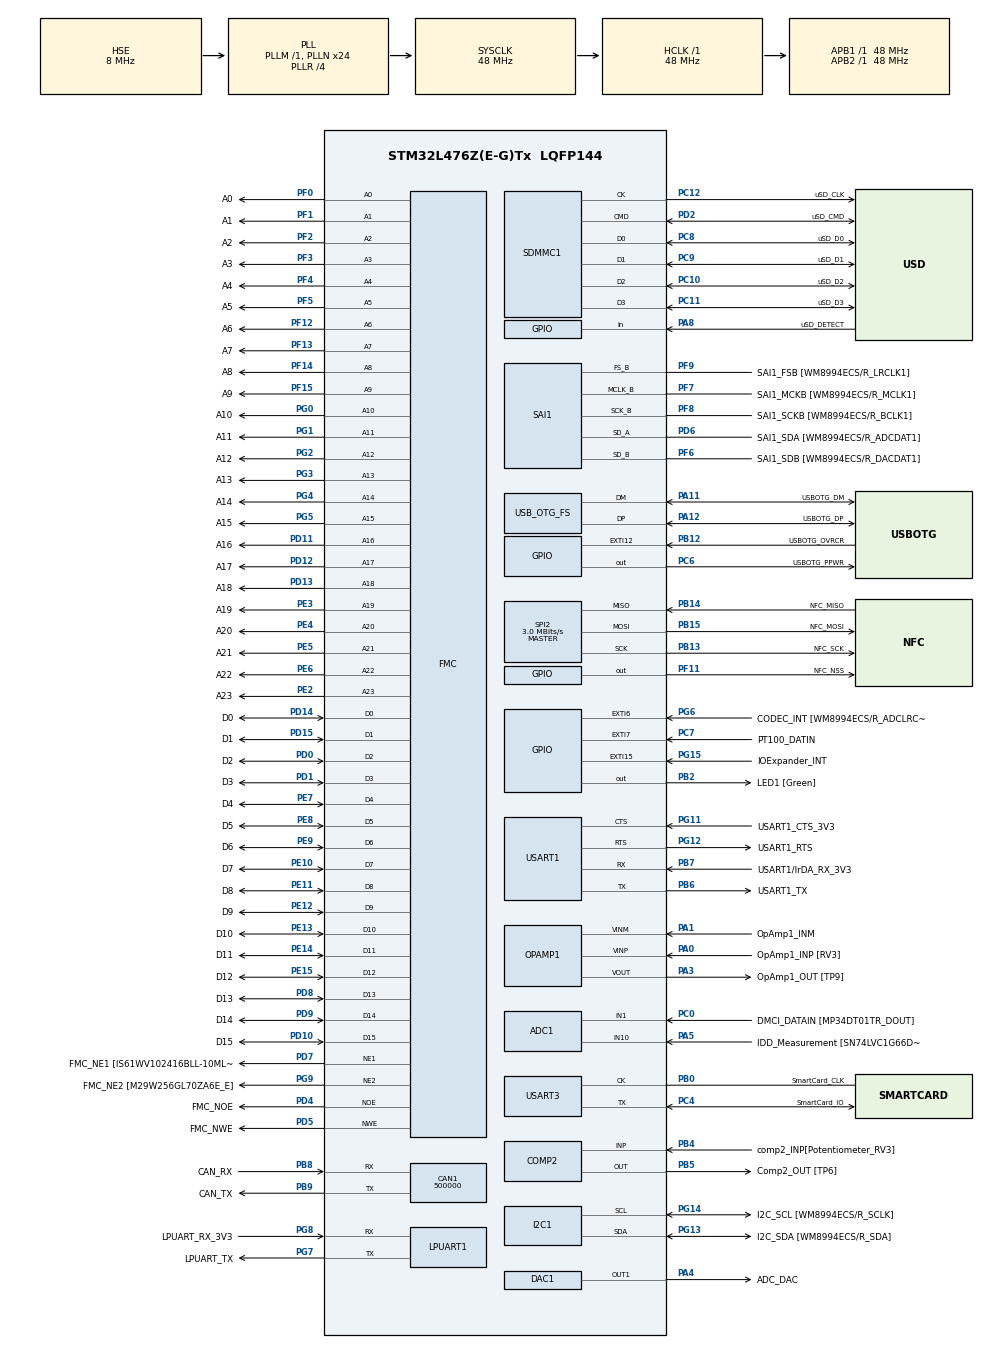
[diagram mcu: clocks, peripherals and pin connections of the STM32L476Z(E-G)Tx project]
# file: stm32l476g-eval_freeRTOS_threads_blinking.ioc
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ADC1.Channel-0\#ChannelRegularConversion=ADC_CHANNEL_10
ADC1.NbrOfConversionFlag=1
ADC1.Offset-0\#ChannelRegularConversion=0
ADC1.OffsetNumber-0\#ChannelRegularConversion=ADC_OFFSET_NONE
ADC1.Rank-0\#ChannelRegularConversion=1
ADC1.SamplingTime-0\#ChannelRegularConversion=ADC_SAMPLETIME_2CYCLES_5
ADC1.master=1
CAN1.BS1=CAN_BS1_1TQ
CAN1.BS2=CAN_BS2_4TQ
CAN1.CalculateBaudRate=500000
CAN1.CalculateTimeBit=2000
CAN1.CalculateTimeQuantum=333.3333333333333
FREERTOS.Tasks01=blink01,24,128,StartBlink01,Default,NULL,Dynamic,NULL,NULL;blink02,16,128,StartBlink02,Default,NULL,Dynamic,NULL,NULL
I2C1.Timing=0x20303E5D
Mcu.Family=STM32L4
Mcu.Name=STM32L476Z(E-G)Tx
Mcu.Package=LQFP144
NVIC.OTG_FS_IRQn=true\:5\:0\:false\:false\:true\:true\:true\:true\:true
NVIC.PriorityGroup=NVIC_PRIORITYGROUP_4
NVIC.TIM6_DAC_IRQn=true\:15\:0\:false\:false\:true\:false\:false\:true\:true
NVIC.TIM7_IRQn=true\:15\:0\:false\:false\:true\:false\:false\:true\:true
NVIC.TimeBase=TIM7_IRQn
NVIC.TimeBaseIP=TIM7
PA0.GPIO_Label=OpAmp1_INP [RV3]
PA0.GPIO_Mode=GPIO_MODE_ANALOG
PA0.GPIO_PuPd=GPIO_NOPULL
PA0.Mode=Standalone
PA0.Signal=OPAMP1_VINP
PA1.GPIO_Label=OpAmp1_INM
PA1.Mode=Standalone
PA1.Signal=OPAMP1_VINM
PA10.GPIO_Label=USBOTG_ID
PA10.Signal=USB_OTG_FS_ID
PA11.GPIO_Label=USBOTG_DM
PA11.GPIO_Mode=GPIO_MODE_AF_PP
PA11.GPIO_PuPd=GPIO_NOPULL
PA11.GPIO_Speed=GPIO_SPEED_FREQ_VERY_HIGH
PA11.Mode=Host_Only
PA11.Signal=USB_OTG_FS_DM
PA12.GPIO_Label=USBOTG_DP
PA12.GPIO_Mode=GPIO_MODE_AF_PP
PA12.GPIO_PuPd=GPIO_NOPULL
PA12.GPIO_Speed=GPIO_SPEED_FREQ_VERY_HIGH
PA12.Mode=Host_Only
PA12.Signal=USB_OTG_FS_DP
PA13\ (JTMS-SWDIO).GPIO_Label=TMS/SWDIO
PA13\ (JTMS-SWDIO).Mode=Serial_Wire
PA13\ (JTMS-SWDIO).Signal=SYS_JTMS-SWDIO
PA14\ (JTCK-SWCLK).GPIO_Label=TMS/SWCLK
PA14\ (JTCK-SWCLK).Mode=Serial_Wire
PA14\ (JTCK-SWCLK).Signal=SYS_JTCK-SWCLK
PA3.GPIO_Label=OpAmp1_OUT [TP9]
PA3.Mode=Standalone
PA3.Signal=OPAMP1_VOUT
PA4.GPIO_Label=ADC_DAC
PA4.GPIO_Mode=GPIO_MODE_ANALOG
PA4.GPIO_PuPd=GPIO_NOPULL
PA4.Signal=COMP_DAC11_group
PA5.GPIO_Label=IDD_Measurement [SN74LVC1G66DCKT_O/I]
PA5.GPIO_Mode=GPIO_MODE_ANALOG_ADC_CONTROL
PA5.GPIO_PuPd=GPIO_NOPULL
PA5.Signal=ADCx_IN10
PA8.GPIO_Label=uSD_DETECT
PA8.Signal=GPIO_Input
PA9.GPIO_Label=USBOTG_VBUS
PA9.Signal=USB_OTG_FS_VBUS
PB0.GPIO_Label=SmartCard_CLK
PB0.Mode=SmartCard_With_Clock
PB0.Signal=USART3_CK
PB12.GPIO_Label=USBOTG_OVRCR
PB12.Signal=GPXTI12
PB13.GPIO_Label=NFC_SCK
PB13.Mode=Full_Duplex_Master
PB13.Signal=SPI2_SCK
PB14.GPIO_Label=NFC_MISO
PB14.Mode=Full_Duplex_Master
PB14.Signal=SPI2_MISO
PB15.GPIO_Label=NFC_MOSI
PB15.Mode=Full_Duplex_Master
PB15.Signal=SPI2_MOSI
PB2.GPIO_Label=LED1 [Green]
PB2.GPIO_ModeDefaultOutputPP=GPIO_MODE_OUTPUT_PP
PB2.GPIO_PuPd=GPIO_NOPULL
PB2.GPIO_Speed=GPIO_SPEED_FREQ_LOW
PB2.Signal=GPIO_Output
PB4\ (NJTRST).GPIO_Label=comp2_INP[Potentiometer_RV3]
PB4\ (NJTRST).Mode=INP
PB4\ (NJTRST).Signal=COMP2_INP
PB5.GPIO_Label=Comp2_OUT [TP6]
PB5.Mode=ExternalOutput
PB5.Signal=COMP2_OUT
PB6.GPIO_FM6=__NULL
PB6.GPIO_Label=USART1_TX
PB6.GPIO_Mode=GPIO_MODE_AF_PP
PB6.GPIO_PuPd=GPIO_PULLUP
PB6.GPIO_Speed=GPIO_SPEED_FREQ_VERY_HIGH
PB6.Mode=Asynchronous
PB6.Signal=USART1_TX
PB7.GPIO_FM7=__NULL
PB7.GPIO_Label=USART1/IrDA_RX_3V3
PB7.GPIO_Mode=GPIO_MODE_AF_PP
PB7.GPIO_PuPd=GPIO_PULLUP
PB7.GPIO_Speed=GPIO_SPEED_FREQ_VERY_HIGH
PB7.Mode=Asynchronous
PB7.Signal=USART1_RX
PB8.GPIO_Label=CAN_RX
PB8.Mode=CAN_Activate
PB8.Signal=CAN1_RX
PB9.GPIO_Label=CAN_TX
PB9.Mode=CAN_Activate
PB9.Signal=CAN1_TX
PC0.GPIO_Label=DMCI_DATAIN [MP34DT01TR_DOUT]
PC0.Signal=ADCx_IN1
PC10.GPIO_Label=uSD_D2
PC10.Mode=SD_4_bits_Wide_bus
PC10.Signal=SDMMC1_D2
PC11.GPIO_Label=uSD_D3
PC11.Mode=SD_4_bits_Wide_bus
PC11.Signal=SDMMC1_D3
PC12.GPIO_Label=uSD_CLK
PC12.Mode=SD_4_bits_Wide_bus
PC12.Signal=SDMMC1_CK
PC13.GPIO_Label=Key [B2]
PC13.Signal=SYS_WKUP2
PC14-OSC32_IN\ (PC14).Mode=LSE-External-Oscillator
PC14-OSC32_IN\ (PC14).Signal=RCC_OSC32_IN
PC15-OSC32_OUT\ (PC15).Mode=LSE-External-Oscillator
PC15-OSC32_OUT\ (PC15).Signal=RCC_OSC32_OUT
PC3.GPIO_Label=VLCD
PC3.GPIO_Mode=GPIO_MODE_AF_PP
PC3.GPIO_PuPd=GPIO_NOPULL
PC3.GPIO_Speed=GPIO_SPEED_FREQ_LOW
PC3.Signal=LCD_VLCD
PC4.GPIO_Label=SmartCard_IO
PC4.Mode=SmartCard_With_Clock
PC4.Signal=USART3_TX
PC5.GPIO_Label=IDD_WAKEUP
PC5.Signal=SYS_WKUP5
PC6.GPIO_Label=USBOTG_PPWR
PC6.Signal=GPIO_Output
PC7.GPIO_Label=PT100_DATIN
PC7.Signal=GPXTI7
PC8.GPIO_Label=uSD_D0
PC8.Mode=SD_4_bits_Wide_bus
PC8.Signal=SDMMC1_D0
PC9.GPIO_Label=uSD_D1
PC9.Mode=SD_4_bits_Wide_bus
PC9.Signal=SDMMC1_D1
PD0.GPIO_Label=D2
PD0.GPIO_Mode=GPIO_MODE_AF_PP
PD0.GPIO_PuPd=GPIO_NOPULL
PD0.GPIO_Speed=GPIO_SPEED_FREQ_VERY_HIGH
PD0.Signal=FMC_D2_DA2
PD1.GPIO_Label=D3
PD1.GPIO_Mode=GPIO_MODE_AF_PP
PD1.GPIO_PuPd=GPIO_NOPULL
PD1.GPIO_Speed=GPIO_SPEED_FREQ_VERY_HIGH
PD1.Signal=FMC_D3_DA3
PD10.GPIO_Label=D15
PD10.Signal=FMC_D15_DA15
PD11.GPIO_Label=A16
PD11.Signal=FMC_A16_CLE
PD12.GPIO_Label=A17
PD12.Signal=FMC_A17_ALE
PD13.GPIO_Label=A18
PD13.Signal=FMC_A18
PD14.GPIO_Label=D0
PD14.Signal=FMC_D0_DA0
PD15.GPIO_Label=D1
PD15.Signal=FMC_D1_DA1
PD2.GPIO_Label=uSD_CMD
PD2.Mode=SD_4_bits_Wide_bus
PD2.Signal=SDMMC1_CMD
PD4.GPIO_Label=FMC_NOE
PD4.GPIO_Mode=GPIO_MODE_AF_PP
PD4.GPIO_PuPd=GPIO_NOPULL
PD4.GPIO_Speed=GPIO_SPEED_FREQ_VERY_HIGH
PD4.Signal=FMC_NOE
PD5.GPIO_Label=FMC_NWE
PD5.GPIO_Mode=GPIO_MODE_AF_PP
PD5.GPIO_PuPd=GPIO_NOPULL
PD5.GPIO_Speed=GPIO_SPEED_FREQ_VERY_HIGH
PD5.Signal=FMC_NWE
PD6.GPIO_Label=SAI1_SDA [WM8994ECS/R_ADCDAT1]
PD6.GPIO_Mode=GPIO_MODE_AF_PP
PD6.GPIO_PuPd=GPIO_NOPULL
PD6.GPIO_Speed=GPIO_SPEED_FREQ_LOW
PD6.Mode=SAI_A_SPDIF
PD6.Signal=SAI1_SD_A
PD7.GPIO_Label=FMC_NE1 [IS61WV102416BLL-10MLI_CE]
PD7.GPIO_Mode=GPIO_MODE_AF_PP
PD7.GPIO_PuPd=GPIO_NOPULL
PD7.GPIO_Speed=GPIO_SPEED_FREQ_VERY_HIGH
PD7.Mode=NorPsramChipSelect1_2
PD7.Signal=FMC_NE1
PD8.GPIO_Label=D13
PD8.Signal=FMC_D13_DA13
PD9.GPIO_Label=D14
PD9.Signal=FMC_D14_DA14
PE0.GPIO_Label=FMC_NBL0 [IS61WV102416BLL-10MLI_BLE]
PE0.Signal=FMC_NBL0
PE1.GPIO_Label=FMC_NBL1 [IS61WV102416BLL-10MLI_BHE]
PE1.Signal=FMC_NBL1
PE10.GPIO_Label=D7
PE10.GPIO_Mode=GPIO_MODE_AF_PP
PE10.GPIO_PuPd=GPIO_NOPULL
PE10.GPIO_Speed=GPIO_SPEED_FREQ_VERY_HIGH
PE10.Signal=FMC_D7_DA7
PE11.GPIO_Label=D8
PE11.GPIO_Mode=GPIO_MODE_AF_PP
PE11.GPIO_PuPd=GPIO_NOPULL
PE11.GPIO_Speed=GPIO_SPEED_FREQ_VERY_HIGH
PE11.Signal=FMC_D8_DA8
PE12.GPIO_Label=D9
PE12.GPIO_Mode=GPIO_MODE_AF_PP
PE12.GPIO_PuPd=GPIO_NOPULL
PE12.GPIO_Speed=GPIO_SPEED_FREQ_VERY_HIGH
PE12.Signal=FMC_D9_DA9
PE13.GPIO_Label=D10
PE13.GPIO_Mode=GPIO_MODE_AF_PP
PE13.GPIO_PuPd=GPIO_NOPULL
PE13.GPIO_Speed=GPIO_SPEED_FREQ_VERY_HIGH
PE13.Signal=FMC_D10_DA10
PE14.GPIO_Label=D11
PE14.GPIO_Mode=GPIO_MODE_AF_PP
PE14.GPIO_PuPd=GPIO_NOPULL
PE14.GPIO_Speed=GPIO_SPEED_FREQ_VERY_HIGH
PE14.Signal=FMC_D11_DA11
PE15.GPIO_Label=D12
PE15.GPIO_Mode=GPIO_MODE_AF_PP
PE15.GPIO_PuPd=GPIO_NOPULL
PE15.GPIO_Speed=GPIO_SPEED_FREQ_VERY_HIGH
PE15.Signal=FMC_D12_DA12
PE2.GPIO_Label=A23
PE2.Signal=FMC_A23
PE3.GPIO_Label=A19
PE3.Signal=FMC_A19
PE4.GPIO_Label=A20
PE4.GPIO_Mode=GPIO_MODE_AF_PP
PE4.GPIO_PuPd=GPIO_NOPULL
PE4.GPIO_Speed=GPIO_SPEED_FREQ_VERY_HIGH
PE4.Signal=FMC_A20
PE5.GPIO_Label=A21
PE5.GPIO_Mode=GPIO_MODE_AF_PP
PE5.GPIO_PuPd=GPIO_NOPULL
PE5.GPIO_Speed=GPIO_SPEED_FREQ_VERY_HIGH
PE5.Signal=FMC_A21
PE6.GPIO_Label=A22
PE6.GPIO_Mode=GPIO_MODE_AF_PP
PE6.GPIO_PuPd=GPIO_NOPULL
PE6.GPIO_Speed=GPIO_SPEED_FREQ_VERY_HIGH
PE6.Signal=FMC_A22
PE7.GPIO_Label=D4
PE7.GPIO_Mode=GPIO_MODE_AF_PP
PE7.GPIO_PuPd=GPIO_NOPULL
PE7.GPIO_Speed=GPIO_SPEED_FREQ_VERY_HIGH
PE7.Signal=FMC_D4_DA4
PE8.GPIO_Label=D5
PE8.GPIO_Mode=GPIO_MODE_AF_PP
PE8.GPIO_PuPd=GPIO_NOPULL
PE8.GPIO_Speed=GPIO_SPEED_FREQ_VERY_HIGH
PE8.Signal=FMC_D5_DA5
PE9.GPIO_Label=D6
PE9.GPIO_Mode=GPIO_MODE_AF_PP
PE9.GPIO_PuPd=GPIO_NOPULL
PE9.GPIO_Speed=GPIO_SPEED_FREQ_VERY_HIGH
PE9.Signal=FMC_D6_DA6
PF0.GPIO_Label=A0
PF0.GPIO_Mode=GPIO_MODE_AF_PP
PF0.GPIO_PuPd=GPIO_NOPULL
PF0.GPIO_Speed=GPIO_SPEED_FREQ_VERY_HIGH
PF0.Signal=FMC_A0
PF1.GPIO_Label=A1
PF1.GPIO_Mode=GPIO_MODE_AF_PP
PF1.GPIO_PuPd=GPIO_NOPULL
PF1.GPIO_Speed=GPIO_SPEED_FREQ_VERY_HIGH
PF1.Signal=FMC_A1
PF11.GPIO_Label=NFC_NSS
PF11.GPIO_ModeDefaultOutputPP=GPIO_MODE_OUTPUT_PP
PF11.GPIO_PuPd=GPIO_NOPULL
PF11.GPIO_Speed=GPIO_SPEED_FREQ_LOW
PF11.Signal=GPIO_Output
PF12.GPIO_Label=A6
PF12.GPIO_Mode=GPIO_MODE_AF_PP
PF12.GPIO_PuPd=GPIO_NOPULL
PF12.GPIO_Speed=GPIO_SPEED_FREQ_VERY_HIGH
PF12.Signal=FMC_A6
PF13.GPIO_Label=A7
PF13.GPIO_Mode=GPIO_MODE_AF_PP
PF13.GPIO_PuPd=GPIO_NOPULL
PF13.GPIO_Speed=GPIO_SPEED_FREQ_VERY_HIGH
PF13.Signal=FMC_A7
PF14.GPIO_Label=A8
PF14.GPIO_Mode=GPIO_MODE_AF_PP
PF14.GPIO_PuPd=GPIO_NOPULL
PF14.GPIO_Speed=GPIO_SPEED_FREQ_VERY_HIGH
PF14.Signal=FMC_A8
PF15.GPIO_Label=A9
PF15.GPIO_Mode=GPIO_MODE_AF_PP
PF15.GPIO_PuPd=GPIO_NOPULL
PF15.GPIO_Speed=GPIO_SPEED_FREQ_VERY_HIGH
PF15.Signal=FMC_A9
PF2.GPIO_Label=A2
PF2.GPIO_Mode=GPIO_MODE_AF_PP
PF2.GPIO_PuPd=GPIO_NOPULL
PF2.GPIO_Speed=GPIO_SPEED_FREQ_VERY_HIGH
PF2.Signal=FMC_A2
PF3.GPIO_Label=A3
PF3.GPIO_Mode=GPIO_MODE_AF_PP
PF3.GPIO_PuPd=GPIO_NOPULL
PF3.GPIO_Speed=GPIO_SPEED_FREQ_VERY_HIGH
PF3.Signal=FMC_A3
PF4.GPIO_Label=A4
PF4.GPIO_Mode=GPIO_MODE_AF_PP
PF4.GPIO_PuPd=GPIO_NOPULL
PF4.GPIO_Speed=GPIO_SPEED_FREQ_VERY_HIGH
PF4.Signal=FMC_A4
PF5.GPIO_Label=A5
PF5.GPIO_Mode=GPIO_MODE_AF_PP
PF5.GPIO_PuPd=GPIO_NOPULL
PF5.GPIO_Speed=GPIO_SPEED_FREQ_VERY_HIGH
PF5.Signal=FMC_A5
PF6.GPIO_Label=SAI1_SDB [WM8994ECS/R_DACDAT1]
PF6.GPIO_Mode=GPIO_MODE_AF_PP
PF6.GPIO_PuPd=GPIO_NOPULL
PF6.GPIO_Speed=GPIO_SPEED_FREQ_LOW
PF6.Mode=SAI_B_MasterWithClock
PF6.Signal=SAI1_SD_B
PF7.GPIO_Label=SAI1_MCKB [WM8994ECS/R_MCLK1]
PF7.GPIO_Mode=GPIO_MODE_AF_PP
PF7.GPIO_PuPd=GPIO_NOPULL
PF7.GPIO_Speed=GPIO_SPEED_FREQ_LOW
PF7.Mode=SAI_B_MasterWithClock
PF7.Signal=SAI1_MCLK_B
PF8.GPIO_Label=SAI1_SCKB [WM8994ECS/R_BCLK1]
PF8.GPIO_Mode=GPIO_MODE_AF_PP
PF8.GPIO_PuPd=GPIO_NOPULL
PF8.GPIO_Speed=GPIO_SPEED_FREQ_LOW
PF8.Mode=SAI_B_MasterWithClock
PF8.Signal=SAI1_SCK_B
PF9.GPIO_Label=SAI1_FSB [WM8994ECS/R_LRCLK1]
PF9.GPIO_Mode=GPIO_MODE_AF_PP
PF9.GPIO_PuPd=GPIO_NOPULL
PF9.GPIO_Speed=GPIO_SPEED_FREQ_LOW
PF9.Mode=SAI_B_MasterWithClock
PF9.Signal=SAI1_FS_B
PG0.GPIO_Label=A10
PG0.GPIO_Mode=GPIO_MODE_AF_PP
PG0.GPIO_PuPd=GPIO_NOPULL
PG0.GPIO_Speed=GPIO_SPEED_FREQ_VERY_HIGH
PG0.Signal=FMC_A10
PG1.GPIO_Label=A11
PG1.GPIO_Mode=GPIO_MODE_AF_PP
PG1.GPIO_PuPd=GPIO_NOPULL
PG1.GPIO_Speed=GPIO_SPEED_FREQ_VERY_HIGH
PG1.Signal=FMC_A11
PG10.GPIO_Label=LCD_NE3 [SN74LVC16T245DGGR_OE]
PG10.GPIO_Mode=GPIO_MODE_AF_PP
PG10.GPIO_PuPd=GPIO_NOPULL
PG10.GPIO_Speed=GPIO_SPEED_FREQ_VERY_HIGH
PG10.Signal=FMC_NE3
PG11.GPIO_Label=USART1_CTS_3V3
PG11.GPIO_Mode=GPIO_MODE_AF_PP
PG11.GPIO_PuPd=GPIO_NOPULL
PG11.GPIO_Speed=GPIO_SPEED_FREQ_VERY_HIGH
PG11.Mode=CTS_RTS
PG11.Signal=USART1_CTS
PG12.GPIO_Label=USART1_RTS
PG12.GPIO_Mode=GPIO_MODE_AF_PP
PG12.GPIO_PuPd=GPIO_NOPULL
PG12.GPIO_Speed=GPIO_SPEED_FREQ_VERY_HIGH
PG12.Mode=CTS_RTS
PG12.Signal=USART1_RTS
PG13.GPIO_Label=I2C_SDA [WM8994ECS/R_SDA]
PG13.GPIO_Mode=GPIO_MODE_AF_OD
PG13.GPIO_Pu=GPIO_PULLUP
PG13.GPIO_Speed=GPIO_SPEED_FREQ_VERY_HIGH
PG13.Mode=I2C
PG13.Signal=I2C1_SDA
PG14.GPIO_Label=I2C_SCL [WM8994ECS/R_SCLK]
PG14.GPIO_Mode=GPIO_MODE_AF_OD
PG14.GPIO_Pu=GPIO_PULLUP
PG14.GPIO_Speed=GPIO_SPEED_FREQ_VERY_HIGH
PG14.Mode=I2C
PG14.Signal=I2C1_SCL
PG15.GPIO_Label=IOExpander_INT
PG15.GPIO_ModeDefaultEXTI=GPIO_MODE_EVT_RISING
PG15.GPIO_PuPd=GPIO_NOPULL
PG15.Signal=GPXTI15
PG2.GPIO_Label=A12
PG2.GPIO_Mode=GPIO_MODE_AF_PP
PG2.GPIO_PuPd=GPIO_NOPULL
PG2.GPIO_Speed=GPIO_SPEED_FREQ_VERY_HIGH
PG2.Signal=FMC_A12
PG3.GPIO_Label=A13
PG3.GPIO_Mode=GPIO_MODE_AF_PP
PG3.GPIO_PuPd=GPIO_NOPULL
PG3.GPIO_Speed=GPIO_SPEED_FREQ_VERY_HIGH
PG3.Signal=FMC_A13
PG4.GPIO_Label=A14
PG4.GPIO_Mode=GPIO_MODE_AF_PP
PG4.GPIO_PuPd=GPIO_NOPULL
PG4.GPIO_Speed=GPIO_SPEED_FREQ_VERY_HIGH
PG4.Signal=FMC_A14
PG5.GPIO_Label=A15
PG5.GPIO_Mode=GPIO_MODE_AF_PP
PG5.GPIO_PuPd=GPIO_NOPULL
PG5.GPIO_Speed=GPIO_SPEED_FREQ_VERY_HIGH
PG5.Signal=FMC_A15
PG6.GPIO_Label=CODEC_INT [WM8994ECS/R_ADCLRCLK1/GPIO1]
PG6.GPIO_ModeDefaultEXTI=GPIO_MODE_EVT_RISING
PG6.GPIO_PuPd=GPIO_NOPULL
PG6.Signal=GPXTI6
PG7.GPIO_Label=LPUART_TX
PG7.GPIO_Mode=GPIO_MODE_AF_PP
PG7.GPIO_PuPd=GPIO_PULLUP
PG7.GPIO_Speed=GPIO_SPEED_FREQ_VERY_HIGH
PG7.Mode=Asynchronous
PG7.Signal=LPUART1_TX
PG8.GPIO_Label=LPUART_RX_3V3
PG8.GPIO_Mode=GPIO_MODE_AF_PP
PG8.GPIO_PuPd=GPIO_PULLUP
PG8.GPIO_Speed=GPIO_SPEED_FREQ_VERY_HIGH
PG8.Mode=Asynchronous
PG8.Signal=LPUART1_RX
PG9.GPIO_Label=FMC_NE2 [M29W256GL70ZA6E_E]
PG9.GPIO_Mode=GPIO_MODE_AF_PP
PG9.GPIO_PuPd=GPIO_NOPULL
PG9.GPIO_Speed=GPIO_SPEED_FREQ_VERY_HIGH
PG9.Mode=NorPsramChipSelect2_1
PG9.Signal=FMC_NE2
PH0-OSC_IN\ (PH0).Mode=HSE-External-Oscillator
PH0-OSC_IN\ (PH0).Signal=RCC_OSC_IN
PH1-OSC_OUT\ (PH1).Mode=HSE-External-Oscillator
PH1-OSC_OUT\ (PH1).Signal=RCC_OSC_OUT
ProjectManager.HeapSize=0x200
ProjectManager.StackSize=0x400
ProjectManager.TargetToolchain=STM32CubeIDE
RCC.ADCFreq_Value=48000000
RCC.AHBFreq_Value=48000000
RCC.APB1Freq_Value=48000000
RCC.APB1TimFreq_Value=48000000
RCC.APB2Freq_Value=48000000
RCC.APB2TimFreq_Value=48000000
RCC.CK48CLockSelection=RCC_USBCLKSOURCE_PLL
RCC.CortexFreq_Value=48000000
RCC.HCLKFreq_Value=48000000
RCC.HSE_VALUE=8000000
RCC.HSI_VALUE=16000000
RCC.MSI_VALUE=4000000
RCC.PLLN=24
RCC.PLLQ=RCC_PLLQ_DIV4
RCC.PLLR=RCC_PLLR_DIV4
RCC.PLLSAI1N=12
RCC.PLLSourceVirtual=RCC_PLLSOURCE_HSE
RCC.SYSCLKFreq_VALUE=48000000
RCC.SYSCLKSource=RCC_SYSCLKSOURCE_PLLCLK
RCC.USBFreq_Value=48000000
RCC.VCOOutputFreq_Value=192000000
SAI1.Instance-SAI_A_SPDIF=SAI$Index_Block_A
SAI1.Instance-SAI_B_MasterWithClock=SAI$Index_Block_B
SAI1.MClockEnable-SAI_B_MasterWithClock=SAI_MASTERCLOCK_ENABLE
SAI1.VirtualMode-SAI_A_SPDIF=VM_SPDIF
SAI1.VirtualMode-SAI_B_MasterWithClock=VM_MASTER
SDMMC1.WideMode=SDMMC_BUS_WIDE_4B
SH.ADCx_IN1.0=ADC1_IN1,IN1-Single-Ended
SH.ADCx_IN10.0=ADC1_IN10,IN10-Single-Ended
SH.COMP_DAC11_group.0=DAC1_OUT1,DAC_OUT1
SH.FMC_A0.0=FMC_A0,24b-a1
SH.FMC_A0.1=FMC_A0,22b-a2
SH.FMC_A1.0=FMC_A1,24b-a1
SH.FMC_A1.1=FMC_A1,22b-a2
SH.FMC_A10.0=FMC_A10,24b-a1
SH.FMC_A10.1=FMC_A10,22b-a2
SH.FMC_A11.0=FMC_A11,24b-a1
SH.FMC_A11.1=FMC_A11,22b-a2
SH.FMC_A12.0=FMC_A12,24b-a1
SH.FMC_A12.1=FMC_A12,22b-a2
SH.FMC_A13.0=FMC_A13,24b-a1
SH.FMC_A13.1=FMC_A13,22b-a2
SH.FMC_A14.0=FMC_A14,24b-a1
SH.FMC_A14.1=FMC_A14,22b-a2
SH.FMC_A15.0=FMC_A15,24b-a1
SH.FMC_A15.1=FMC_A15,22b-a2
SH.FMC_A16_CLE.0=FMC_A16,24b-a1
SH.FMC_A16_CLE.1=FMC_A16,22b-a2
SH.FMC_A17_ALE.0=FMC_A17,24b-a1
SH.FMC_A17_ALE.1=FMC_A17,22b-a2
SH.FMC_A18.0=FMC_A18,24b-a1
SH.FMC_A18.1=FMC_A18,22b-a2
SH.FMC_A19.0=FMC_A19,24b-a1
SH.FMC_A19.1=FMC_A19,22b-a2
SH.FMC_A2.0=FMC_A2,24b-a1
SH.FMC_A2.1=FMC_A2,22b-a2
SH.FMC_A20.0=FMC_A20,24b-a1
SH.FMC_A20.1=FMC_A20,22b-a2
SH.FMC_A21.0=FMC_A21,24b-a1
SH.FMC_A21.1=FMC_A21,22b-a2
SH.FMC_A22.0=FMC_A22,24b-a1
SH.FMC_A23.0=FMC_A23,24b-a1
SH.FMC_A3.0=FMC_A3,24b-a1
SH.FMC_A3.1=FMC_A3,22b-a2
SH.FMC_A4.0=FMC_A4,24b-a1
SH.FMC_A4.1=FMC_A4,22b-a2
SH.FMC_A5.0=FMC_A5,24b-a1
SH.FMC_A5.1=FMC_A5,22b-a2
SH.FMC_A6.0=FMC_A6,24b-a1
SH.FMC_A6.1=FMC_A6,22b-a2
SH.FMC_A7.0=FMC_A7,24b-a1
SH.FMC_A7.1=FMC_A7,22b-a2
SH.FMC_A8.0=FMC_A8,24b-a1
SH.FMC_A8.1=FMC_A8,22b-a2
SH.FMC_A9.0=FMC_A9,24b-a1
SH.FMC_A9.1=FMC_A9,22b-a2
SH.FMC_D0_DA0.0=FMC_D0,16b-d1
SH.FMC_D0_DA0.1=FMC_D0,16b-d2
SH.FMC_D10_DA10.0=FMC_D10,16b-d1
SH.FMC_D10_DA10.1=FMC_D10,16b-d2
SH.FMC_D11_DA11.0=FMC_D11,16b-d1
SH.FMC_D11_DA11.1=FMC_D11,16b-d2
SH.FMC_D12_DA12.0=FMC_D12,16b-d1
SH.FMC_D12_DA12.1=FMC_D12,16b-d2
SH.FMC_D13_DA13.0=FMC_D13,16b-d1
SH.FMC_D13_DA13.1=FMC_D13,16b-d2
SH.FMC_D14_DA14.0=FMC_D14,16b-d1
SH.FMC_D14_DA14.1=FMC_D14,16b-d2
SH.FMC_D15_DA15.0=FMC_D15,16b-d1
SH.FMC_D15_DA15.1=FMC_D15,16b-d2
SH.FMC_D1_DA1.0=FMC_D1,16b-d1
SH.FMC_D1_DA1.1=FMC_D1,16b-d2
SH.FMC_D2_DA2.0=FMC_D2,16b-d1
SH.FMC_D2_DA2.1=FMC_D2,16b-d2
SH.FMC_D3_DA3.0=FMC_D3,16b-d1
SH.FMC_D3_DA3.1=FMC_D3,16b-d2
SH.FMC_D4_DA4.0=FMC_D4,16b-d1
SH.FMC_D4_DA4.1=FMC_D4,16b-d2
SH.FMC_D5_DA5.0=FMC_D5,16b-d1
SH.FMC_D5_DA5.1=FMC_D5,16b-d2
SH.FMC_D6_DA6.0=FMC_D6,16b-d1
SH.FMC_D6_DA6.1=FMC_D6,16b-d2
SH.FMC_D7_DA7.0=FMC_D7,16b-d1
SH.FMC_D7_DA7.1=FMC_D7,16b-d2
SH.FMC_D8_DA8.0=FMC_D8,16b-d1
SH.FMC_D8_DA8.1=FMC_D8,16b-d2
SH.FMC_D9_DA9.0=FMC_D9,16b-d1
SH.FMC_D9_DA9.1=FMC_D9,16b-d2
SH.FMC_NBL0.0=FMC_NBL0
SH.FMC_NBL1.0=FMC_NBL1
SH.FMC_NOE.0=FMC_NOE,NorFlash1
SH.FMC_NOE.1=FMC_NOE,Sram2
SH.FMC_NWE.0=FMC_NWE,NorFlash1
SH.FMC_NWE.1=FMC_NWE,Sram2
SPI2.BaudRatePrescaler=SPI_BAUDRATEPRESCALER_16
SPI2.CalculateBaudRate=3.0 MBits/s
SPI2.Direction=SPI_DIRECTION_2LINES
SPI2.Mode=SPI_MODE_MASTER
SPI2.VirtualType=VM_MASTER
USART1.VirtualMode-Asynchronous=VM_ASYNC
USART3.CalculateSpeed=2.4 MHz
USART3.VirtualClockMode=VM_SMARTCARD
USART3.VirtualMode-SmartCard_With_Clock=VM_SMARTCARD
USB_OTG_FS.VirtualMode=Host_Only
USB_OTG_FS.phy_itface=HCD_PHY_EMBEDDED
VP_COMP2_VS_VREFINT.Mode=VREFINT
VP_FREERTOS_VS_CMSIS_V2.Mode=CMSIS_V2
VP_SYS_VS_tim7.Mode=TIM7
board=STM32L476G-EVAL

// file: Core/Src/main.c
/* USER CODE BEGIN Header */
/**
  ******************************************************************************
  * @file           : main.c
  * @brief          : Main program body
  ******************************************************************************
  * @attention
  *
  * Copyright (c) 2022 STMicroelectronics.
  * All rights reserved.
  *
  * This software is licensed under terms that can be found in the LICENSE file
  * in the root directory of this software component.
  * If no LICENSE file comes with this software, it is provided AS-IS.
  *
  ******************************************************************************
  */
/* USER CODE END Header */
#include "main.h"
#include "cmsis_os.h"

 ADC_HandleTypeDef hadc1;

CAN_HandleTypeDef hcan1;

COMP_HandleTypeDef hcomp2;

DAC_HandleTypeDef hdac1;

I2C_HandleTypeDef hi2c1;

UART_HandleTypeDef hlpuart1;
UART_HandleTypeDef huart1;
SMARTCARD_HandleTypeDef hsmartcard3;

OPAMP_HandleTypeDef hopamp1;

SAI_HandleTypeDef hsai_BlockA1;
SAI_HandleTypeDef hsai_BlockB1;

SD_HandleTypeDef hsd1;

SPI_HandleTypeDef hspi2;

HCD_HandleTypeDef hhcd_USB_OTG_FS;

NOR_HandleTypeDef hnor1;
SRAM_HandleTypeDef hsram2;

/* Definitions for blink01 */
osThreadId_t blink01Handle;
const osThreadAttr_t blink01_attributes = {
  .name = "blink01",
  .stack_size = 128 * 4,
  .priority = (osPriority_t) osPriorityNormal,
};
/* Definitions for blink02 */
osThreadId_t blink02Handle;
const osThreadAttr_t blink02_attributes = {
  .name = "blink02",
  .stack_size = 128 * 4,
  .priority = (osPriority_t) osPriorityBelowNormal,
};

void SystemClock_Config(void);
void PeriphCommonClock_Config(void);
static void MX_GPIO_Init(void);
static void MX_ADC1_Init(void);
static void MX_CAN1_Init(void);
static void MX_COMP2_Init(void);
static void MX_DAC1_Init(void);
static void MX_FMC_Init(void);
static void MX_I2C1_Init(void);
static void MX_LPUART1_UART_Init(void);
static void MX_USART1_UART_Init(void);
static void MX_USART3_SMARTCARD_Init(void);
static void MX_OPAMP1_Init(void);
static void MX_SAI1_Init(void);
static void MX_SDMMC1_SD_Init(void);
static void MX_SPI2_Init(void);
static void MX_USB_OTG_FS_HCD_Init(void);
void StartBlink01(void *argument);
void StartBlink02(void *argument);

int main(void)
{

  /* MCU Configuration--------------------------------------------------------*/

  /* Reset of all peripherals, Initializes the Flash interface and the Systick. */
  HAL_Init();

  /* Configure the system clock */
  SystemClock_Config();

/* Configure the peripherals common clocks */
  PeriphCommonClock_Config();

  /* Initialize all configured peripherals */
  MX_GPIO_Init();
  MX_ADC1_Init();
  MX_CAN1_Init();
  MX_COMP2_Init();
  MX_DAC1_Init();
  MX_FMC_Init();
  MX_I2C1_Init();
  MX_LPUART1_UART_Init();
  MX_USART1_UART_Init();
  MX_USART3_SMARTCARD_Init();
  MX_OPAMP1_Init();
  MX_SAI1_Init();
  MX_SDMMC1_SD_Init();
  MX_SPI2_Init();
  MX_USB_OTG_FS_HCD_Init();

  /* Init scheduler */
  osKernelInitialize();

  /* Create the thread(s) */
  /* creation of blink01 */
  blink01Handle = osThreadNew(StartBlink01, NULL, &blink01_attributes);

  /* creation of blink02 */
  blink02Handle = osThreadNew(StartBlink02, NULL, &blink02_attributes);

  /* Start scheduler */
  osKernelStart();

  /* We should never get here as control is now taken by the scheduler */
  /* Infinite loop */
  while (1)
  {

  }
}

void SystemClock_Config(void)
{
  RCC_OscInitTypeDef RCC_OscInitStruct = {0};
  RCC_ClkInitTypeDef RCC_ClkInitStruct = {0};

  /** Configure the main internal regulator output voltage
  */
  if (HAL_PWREx_ControlVoltageScaling(PWR_REGULATOR_VOLTAGE_SCALE1) != HAL_OK)
  {
    Error_Handler();
  }

  /** Initializes the RCC Oscillators according to the specified parameters
  * in the RCC_OscInitTypeDef structure.
  */
  RCC_OscInitStruct.OscillatorType = RCC_OSCILLATORTYPE_HSE;
  RCC_OscInitStruct.HSEState = RCC_HSE_ON;
  RCC_OscInitStruct.PLL.PLLState = RCC_PLL_ON;
  RCC_OscInitStruct.PLL.PLLSource = RCC_PLLSOURCE_HSE;
  RCC_OscInitStruct.PLL.PLLM = 1;
  RCC_OscInitStruct.PLL.PLLN = 24;
  RCC_OscInitStruct.PLL.PLLP = RCC_PLLP_DIV7;
  RCC_OscInitStruct.PLL.PLLQ = RCC_PLLQ_DIV4;
  RCC_OscInitStruct.PLL.PLLR = RCC_PLLR_DIV4;
  if (HAL_RCC_OscConfig(&RCC_OscInitStruct) != HAL_OK)
  {
    Error_Handler();
  }

  /** Initializes the CPU, AHB and APB buses clocks
  */
  RCC_ClkInitStruct.ClockType = RCC_CLOCKTYPE_HCLK|RCC_CLOCKTYPE_SYSCLK
                              |RCC_CLOCKTYPE_PCLK1|RCC_CLOCKTYPE_PCLK2;
  RCC_ClkInitStruct.SYSCLKSource = RCC_SYSCLKSOURCE_PLLCLK;
  RCC_ClkInitStruct.AHBCLKDivider = RCC_SYSCLK_DIV1;
  RCC_ClkInitStruct.APB1CLKDivider = RCC_HCLK_DIV1;
  RCC_ClkInitStruct.APB2CLKDivider = RCC_HCLK_DIV1;

  if (HAL_RCC_ClockConfig(&RCC_ClkInitStruct, FLASH_LATENCY_2) != HAL_OK)
  {
    Error_Handler();
  }
}

void PeriphCommonClock_Config(void)
{
  RCC_PeriphCLKInitTypeDef PeriphClkInit = {0};

  /** Initializes the peripherals clock
  */
  PeriphClkInit.PeriphClockSelection = RCC_PERIPHCLK_SAI1|RCC_PERIPHCLK_ADC;
  PeriphClkInit.Sai1ClockSelection = RCC_SAI1CLKSOURCE_PLLSAI1;
  PeriphClkInit.AdcClockSelection = RCC_ADCCLKSOURCE_PLLSAI1;
  PeriphClkInit.PLLSAI1.PLLSAI1Source = RCC_PLLSOURCE_HSE;
  PeriphClkInit.PLLSAI1.PLLSAI1M = 1;
  PeriphClkInit.PLLSAI1.PLLSAI1N = 12;
  PeriphClkInit.PLLSAI1.PLLSAI1P = RCC_PLLP_DIV7;
  PeriphClkInit.PLLSAI1.PLLSAI1Q = RCC_PLLQ_DIV2;
  PeriphClkInit.PLLSAI1.PLLSAI1R = RCC_PLLR_DIV2;
  PeriphClkInit.PLLSAI1.PLLSAI1ClockOut = RCC_PLLSAI1_SAI1CLK|RCC_PLLSAI1_ADC1CLK;
  if (HAL_RCCEx_PeriphCLKConfig(&PeriphClkInit) != HAL_OK)
  {
    Error_Handler();
  }
}

static void MX_ADC1_Init(void)
{

  ADC_MultiModeTypeDef multimode = {0};
  ADC_ChannelConfTypeDef sConfig = {0};

  /** Common config
  */
  hadc1.Instance = ADC1;
  hadc1.Init.ClockPrescaler = ADC_CLOCK_ASYNC_DIV1;
  hadc1.Init.Resolution = ADC_RESOLUTION_12B;
  hadc1.Init.DataAlign = ADC_DATAALIGN_RIGHT;
  hadc1.Init.ScanConvMode = ADC_SCAN_DISABLE;
  hadc1.Init.EOCSelection = ADC_EOC_SINGLE_CONV;
  hadc1.Init.LowPowerAutoWait = DISABLE;
  hadc1.Init.ContinuousConvMode = DISABLE;
  hadc1.Init.NbrOfConversion = 1;
  hadc1.Init.DiscontinuousConvMode = DISABLE;
  hadc1.Init.ExternalTrigConv = ADC_SOFTWARE_START;
  hadc1.Init.ExternalTrigConvEdge = ADC_EXTERNALTRIGCONVEDGE_NONE;
  hadc1.Init.DMAContinuousRequests = DISABLE;
  hadc1.Init.Overrun = ADC_OVR_DATA_PRESERVED;
  hadc1.Init.OversamplingMode = DISABLE;
  if (HAL_ADC_Init(&hadc1) != HAL_OK)
  {
    Error_Handler();
  }

  /** Configure the ADC multi-mode
  */
  multimode.Mode = ADC_MODE_INDEPENDENT;
  if (HAL_ADCEx_MultiModeConfigChannel(&hadc1, &multimode) != HAL_OK)
  {
    Error_Handler();
  }

  /** Configure Regular Channel
  */
  sConfig.Channel = ADC_CHANNEL_10;
  sConfig.Rank = ADC_REGULAR_RANK_1;
  sConfig.SamplingTime = ADC_SAMPLETIME_2CYCLES_5;
  sConfig.SingleDiff = ADC_SINGLE_ENDED;
  sConfig.OffsetNumber = ADC_OFFSET_NONE;
  sConfig.Offset = 0;
  if (HAL_ADC_ConfigChannel(&hadc1, &sConfig) != HAL_OK)
  {
    Error_Handler();
  }

}

static void MX_CAN1_Init(void)
{

  hcan1.Instance = CAN1;
  hcan1.Init.Prescaler = 16;
  hcan1.Init.Mode = CAN_MODE_NORMAL;
  hcan1.Init.SyncJumpWidth = CAN_SJW_1TQ;
  hcan1.Init.TimeSeg1 = CAN_BS1_1TQ;
  hcan1.Init.TimeSeg2 = CAN_BS2_4TQ;
  hcan1.Init.TimeTriggeredMode = DISABLE;
  hcan1.Init.AutoBusOff = DISABLE;
  hcan1.Init.AutoWakeUp = DISABLE;
  hcan1.Init.AutoRetransmission = DISABLE;
  hcan1.Init.ReceiveFifoLocked = DISABLE;
  hcan1.Init.TransmitFifoPriority = DISABLE;
  if (HAL_CAN_Init(&hcan1) != HAL_OK)
  {
    Error_Handler();
  }

}

static void MX_COMP2_Init(void)
{

  hcomp2.Instance = COMP2;
  hcomp2.Init.InvertingInput = COMP_INPUT_MINUS_VREFINT;
  hcomp2.Init.NonInvertingInput = COMP_INPUT_PLUS_IO1;
  hcomp2.Init.OutputPol = COMP_OUTPUTPOL_NONINVERTED;
  hcomp2.Init.Hysteresis = COMP_HYSTERESIS_NONE;
  hcomp2.Init.BlankingSrce = COMP_BLANKINGSRC_NONE;
  hcomp2.Init.Mode = COMP_POWERMODE_HIGHSPEED;
  hcomp2.Init.WindowMode = COMP_WINDOWMODE_DISABLE;
  hcomp2.Init.TriggerMode = COMP_TRIGGERMODE_NONE;
  if (HAL_COMP_Init(&hcomp2) != HAL_OK)
  {
    Error_Handler();
  }

}

static void MX_DAC1_Init(void)
{

  DAC_ChannelConfTypeDef sConfig = {0};

  /** DAC Initialization
  */
  hdac1.Instance = DAC1;
  if (HAL_DAC_Init(&hdac1) != HAL_OK)
  {
    Error_Handler();
  }

  /** DAC channel OUT1 config
  */
  sConfig.DAC_SampleAndHold = DAC_SAMPLEANDHOLD_DISABLE;
  sConfig.DAC_Trigger = DAC_TRIGGER_NONE;
  sConfig.DAC_OutputBuffer = DAC_OUTPUTBUFFER_ENABLE;
  sConfig.DAC_ConnectOnChipPeripheral = DAC_CHIPCONNECT_DISABLE;
  sConfig.DAC_UserTrimming = DAC_TRIMMING_FACTORY;
  if (HAL_DAC_ConfigChannel(&hdac1, &sConfig, DAC_CHANNEL_1) != HAL_OK)
  {
    Error_Handler();
  }

}

static void MX_I2C1_Init(void)
{

  hi2c1.Instance = I2C1;
  hi2c1.Init.Timing = 0x20303E5D;
  hi2c1.Init.OwnAddress1 = 0;
  hi2c1.Init.AddressingMode = I2C_ADDRESSINGMODE_7BIT;
  hi2c1.Init.DualAddressMode = I2C_DUALADDRESS_DISABLE;
  hi2c1.Init.OwnAddress2 = 0;
  hi2c1.Init.OwnAddress2Masks = I2C_OA2_NOMASK;
  hi2c1.Init.GeneralCallMode = I2C_GENERALCALL_DISABLE;
  hi2c1.Init.NoStretchMode = I2C_NOSTRETCH_DISABLE;
  if (HAL_I2C_Init(&hi2c1) != HAL_OK)
  {
    Error_Handler();
  }

  /** Configure Analogue filter
  */
  if (HAL_I2CEx_ConfigAnalogFilter(&hi2c1, I2C_ANALOGFILTER_ENABLE) != HAL_OK)
  {
    Error_Handler();
  }

  /** Configure Digital filter
  */
  if (HAL_I2CEx_ConfigDigitalFilter(&hi2c1, 0) != HAL_OK)
  {
    Error_Handler();
  }

}

static void MX_LPUART1_UART_Init(void)
{

  hlpuart1.Instance = LPUART1;
  hlpuart1.Init.BaudRate = 209700;
  hlpuart1.Init.WordLength = UART_WORDLENGTH_7B;
  hlpuart1.Init.StopBits = UART_STOPBITS_1;
  hlpuart1.Init.Parity = UART_PARITY_NONE;
  hlpuart1.Init.Mode = UART_MODE_TX_RX;
  hlpuart1.Init.HwFlowCtl = UART_HWCONTROL_NONE;
  hlpuart1.Init.OneBitSampling = UART_ONE_BIT_SAMPLE_DISABLE;
  hlpuart1.AdvancedInit.AdvFeatureInit = UART_ADVFEATURE_NO_INIT;
  if (HAL_UART_Init(&hlpuart1) != HAL_OK)
  {
    Error_Handler();
  }

}

static void MX_USART1_UART_Init(void)
{

  huart1.Instance = USART1;
  huart1.Init.BaudRate = 115200;
  huart1.Init.WordLength = UART_WORDLENGTH_8B;
  huart1.Init.StopBits = UART_STOPBITS_1;
  huart1.Init.Parity = UART_PARITY_NONE;
  huart1.Init.Mode = UART_MODE_TX_RX;
  huart1.Init.HwFlowCtl = UART_HWCONTROL_RTS_CTS;
  huart1.Init.OverSampling = UART_OVERSAMPLING_16;
  huart1.Init.OneBitSampling = UART_ONE_BIT_SAMPLE_DISABLE;
  huart1.AdvancedInit.AdvFeatureInit = UART_ADVFEATURE_NO_INIT;
  if (HAL_UART_Init(&huart1) != HAL_OK)
  {
    Error_Handler();
  }

}

static void MX_USART3_SMARTCARD_Init(void)
{

  hsmartcard3.Instance = USART3;
  hsmartcard3.Init.BaudRate = 115200;
  hsmartcard3.Init.WordLength = SMARTCARD_WORDLENGTH_9B;
  hsmartcard3.Init.StopBits = SMARTCARD_STOPBITS_1_5;
  hsmartcard3.Init.Parity = SMARTCARD_PARITY_EVEN;
  hsmartcard3.Init.Mode = SMARTCARD_MODE_TX_RX;
  hsmartcard3.Init.CLKPolarity = SMARTCARD_POLARITY_LOW;
  hsmartcard3.Init.CLKPhase = SMARTCARD_PHASE_1EDGE;
  hsmartcard3.Init.CLKLastBit = SMARTCARD_LASTBIT_DISABLE;
  hsmartcard3.Init.OneBitSampling = SMARTCARD_ONE_BIT_SAMPLE_DISABLE;
  hsmartcard3.Init.Prescaler = 10;
  hsmartcard3.Init.GuardTime = 0;
  hsmartcard3.Init.NACKEnable = SMARTCARD_NACK_DISABLE;
  hsmartcard3.Init.TimeOutEnable = SMARTCARD_TIMEOUT_DISABLE;
  hsmartcard3.Init.BlockLength = 0;
  hsmartcard3.Init.AutoRetryCount = 0;
  hsmartcard3.AdvancedInit.AdvFeatureInit = SMARTCARD_ADVFEATURE_NO_INIT;
  if (HAL_SMARTCARD_Init(&hsmartcard3) != HAL_OK)
  {
    Error_Handler();
  }

}

static void MX_OPAMP1_Init(void)
{

  hopamp1.Instance = OPAMP1;
  hopamp1.Init.PowerSupplyRange = OPAMP_POWERSUPPLY_LOW;
  hopamp1.Init.Mode = OPAMP_STANDALONE_MODE;
  hopamp1.Init.NonInvertingInput = OPAMP_NONINVERTINGINPUT_IO0;
  hopamp1.Init.InvertingInput = OPAMP_INVERTINGINPUT_IO0;
  hopamp1.Init.PowerMode = OPAMP_POWERMODE_NORMALPOWER;
  hopamp1.Init.UserTrimming = OPAMP_TRIMMING_FACTORY;
  if (HAL_OPAMP_Init(&hopamp1) != HAL_OK)
  {
    Error_Handler();
  }

}

static void MX_SAI1_Init(void)
{

  hsai_BlockA1.Instance = SAI1_Block_A;
  hsai_BlockA1.Init.Protocol = SAI_SPDIF_PROTOCOL;
  hsai_BlockA1.Init.AudioMode = SAI_MODEMASTER_TX;
  hsai_BlockA1.Init.Synchro = SAI_ASYNCHRONOUS;
  hsai_BlockA1.Init.OutputDrive = SAI_OUTPUTDRIVE_DISABLE;
  hsai_BlockA1.Init.FIFOThreshold = SAI_FIFOTHRESHOLD_EMPTY;
  hsai_BlockA1.Init.AudioFrequency = SAI_AUDIO_FREQUENCY_48K;
  hsai_BlockA1.Init.SynchroExt = SAI_SYNCEXT_DISABLE;
  hsai_BlockA1.Init.MonoStereoMode = SAI_STEREOMODE;
  hsai_BlockA1.Init.CompandingMode = SAI_NOCOMPANDING;
  if (HAL_SAI_Init(&hsai_BlockA1) != HAL_OK)
  {
    Error_Handler();
  }
  hsai_BlockB1.Instance = SAI1_Block_B;
  hsai_BlockB1.Init.Protocol = SAI_FREE_PROTOCOL;
  hsai_BlockB1.Init.AudioMode = SAI_MODEMASTER_TX;
  hsai_BlockB1.Init.DataSize = SAI_DATASIZE_8;
  hsai_BlockB1.Init.FirstBit = SAI_FIRSTBIT_MSB;
  hsai_BlockB1.Init.ClockStrobing = SAI_CLOCKSTROBING_FALLINGEDGE;
  hsai_BlockB1.Init.Synchro = SAI_ASYNCHRONOUS;
  hsai_BlockB1.Init.OutputDrive = SAI_OUTPUTDRIVE_DISABLE;
  hsai_BlockB1.Init.NoDivider = SAI_MASTERDIVIDER_ENABLE;
  hsai_BlockB1.Init.FIFOThreshold = SAI_FIFOTHRESHOLD_EMPTY;
  hsai_BlockB1.Init.AudioFrequency = SAI_AUDIO_FREQUENCY_192K;
  hsai_BlockB1.Init.SynchroExt = SAI_SYNCEXT_DISABLE;
  hsai_BlockB1.Init.MonoStereoMode = SAI_STEREOMODE;
  hsai_BlockB1.Init.CompandingMode = SAI_NOCOMPANDING;
  hsai_BlockB1.Init.TriState = SAI_OUTPUT_NOTRELEASED;
  hsai_BlockB1.FrameInit.FrameLength = 8;
  hsai_BlockB1.FrameInit.ActiveFrameLength = 1;
  hsai_BlockB1.FrameInit.FSDefinition = SAI_FS_STARTFRAME;
  hsai_BlockB1.FrameInit.FSPolarity = SAI_FS_ACTIVE_LOW;
  hsai_BlockB1.FrameInit.FSOffset = SAI_FS_FIRSTBIT;
  hsai_BlockB1.SlotInit.FirstBitOffset = 0;
  hsai_BlockB1.SlotInit.SlotSize = SAI_SLOTSIZE_DATASIZE;
  hsai_BlockB1.SlotInit.SlotNumber = 1;
  hsai_BlockB1.SlotInit.SlotActive = 0x00000000;
  if (HAL_SAI_Init(&hsai_BlockB1) != HAL_OK)
  {
    Error_Handler();
  }

}

static void MX_SDMMC1_SD_Init(void)
{

  hsd1.Instance = SDMMC1;
  hsd1.Init.ClockEdge = SDMMC_CLOCK_EDGE_RISING;
  hsd1.Init.ClockBypass = SDMMC_CLOCK_BYPASS_DISABLE;
  hsd1.Init.ClockPowerSave = SDMMC_CLOCK_POWER_SAVE_DISABLE;
  hsd1.Init.BusWide = SDMMC_BUS_WIDE_1B;
  hsd1.Init.HardwareFlowControl = SDMMC_HARDWARE_FLOW_CONTROL_DISABLE;
  hsd1.Init.ClockDiv = 0;
  if (HAL_SD_Init(&hsd1) != HAL_OK)
  {
    Error_Handler();
  }
  if (HAL_SD_ConfigWideBusOperation(&hsd1, SDMMC_BUS_WIDE_4B) != HAL_OK)
  {
    Error_Handler();
  }

}

static void MX_SPI2_Init(void)
{

  /* SPI2 parameter configuration*/
  hspi2.Instance = SPI2;
  hspi2.Init.Mode = SPI_MODE_MASTER;
  hspi2.Init.Direction = SPI_DIRECTION_2LINES;
  hspi2.Init.DataSize = SPI_DATASIZE_4BIT;
  hspi2.Init.CLKPolarity = SPI_POLARITY_LOW;
  hspi2.Init.CLKPhase = SPI_PHASE_1EDGE;
  hspi2.Init.NSS = SPI_NSS_SOFT;
  hspi2.Init.BaudRatePrescaler = SPI_BAUDRATEPRESCALER_16;
  hspi2.Init.FirstBit = SPI_FIRSTBIT_MSB;
  hspi2.Init.TIMode = SPI_TIMODE_DISABLE;
  hspi2.Init.CRCCalculation = SPI_CRCCALCULATION_DISABLE;
  hspi2.Init.CRCPolynomial = 7;
  hspi2.Init.CRCLength = SPI_CRC_LENGTH_DATASIZE;
  hspi2.Init.NSSPMode = SPI_NSS_PULSE_ENABLE;
  if (HAL_SPI_Init(&hspi2) != HAL_OK)
  {
    Error_Handler();
  }

}

static void MX_USB_OTG_FS_HCD_Init(void)
{

  hhcd_USB_OTG_FS.Instance = USB_OTG_FS;
  hhcd_USB_OTG_FS.Init.Host_channels = 8;
  hhcd_USB_OTG_FS.Init.speed = HCD_SPEED_FULL;
  hhcd_USB_OTG_FS.Init.dma_enable = DISABLE;
  hhcd_USB_OTG_FS.Init.phy_itface = HCD_PHY_EMBEDDED;
  hhcd_USB_OTG_FS.Init.Sof_enable = DISABLE;
  if (HAL_HCD_Init(&hhcd_USB_OTG_FS) != HAL_OK)
  {
    Error_Handler();
  }

}

/* FMC initialization function */
static void MX_FMC_Init(void)
{

  FMC_NORSRAM_TimingTypeDef Timing = {0};

  /** Perform the NOR1 memory initialization sequence
  */
  hnor1.Instance = FMC_NORSRAM_DEVICE;
  hnor1.Extended = FMC_NORSRAM_EXTENDED_DEVICE;
  /* hnor1.Init */
  hnor1.Init.NSBank = FMC_NORSRAM_BANK2;
  hnor1.Init.DataAddressMux = FMC_DATA_ADDRESS_MUX_DISABLE;
  hnor1.Init.MemoryType = FMC_MEMORY_TYPE_NOR;
  hnor1.Init.MemoryDataWidth = FMC_NORSRAM_MEM_BUS_WIDTH_16;
  hnor1.Init.BurstAccessMode = FMC_BURST_ACCESS_MODE_DISABLE;
  hnor1.Init.WaitSignalPolarity = FMC_WAIT_SIGNAL_POLARITY_LOW;
  hnor1.Init.WaitSignalActive = FMC_WAIT_TIMING_BEFORE_WS;
  hnor1.Init.WriteOperation = FMC_WRITE_OPERATION_DISABLE;
  hnor1.Init.WaitSignal = FMC_WAIT_SIGNAL_DISABLE;
  hnor1.Init.ExtendedMode = FMC_EXTENDED_MODE_DISABLE;
  hnor1.Init.AsynchronousWait = FMC_ASYNCHRONOUS_WAIT_DISABLE;
  hnor1.Init.WriteBurst = FMC_WRITE_BURST_DISABLE;
  hnor1.Init.ContinuousClock = FMC_CONTINUOUS_CLOCK_SYNC_ONLY;
  hnor1.Init.PageSize = FMC_PAGE_SIZE_NONE;
  /* Timing */
  Timing.AddressSetupTime = 15;
  Timing.AddressHoldTime = 15;
  Timing.DataSetupTime = 255;
  Timing.BusTurnAroundDuration = 15;
  Timing.CLKDivision = 16;
  Timing.DataLatency = 17;
  Timing.AccessMode = FMC_ACCESS_MODE_A;
  /* ExtTiming */

  if (HAL_NOR_Init(&hnor1, &Timing, NULL) != HAL_OK)
  {
    Error_Handler( );
  }

  /** Perform the SRAM2 memory initialization sequence
  */
  hsram2.Instance = FMC_NORSRAM_DEVICE;
  hsram2.Extended = FMC_NORSRAM_EXTENDED_DEVICE;
  /* hsram2.Init */
  hsram2.Init.NSBank = FMC_NORSRAM_BANK1;
  hsram2.Init.DataAddressMux = FMC_DATA_ADDRESS_MUX_DISABLE;
  hsram2.Init.MemoryType = FMC_MEMORY_TYPE_SRAM;
  hsram2.Init.MemoryDataWidth = FMC_NORSRAM_MEM_BUS_WIDTH_16;
  hsram2.Init.BurstAccessMode = FMC_BURST_ACCESS_MODE_DISABLE;
  hsram2.Init.WaitSignalPolarity = FMC_WAIT_SIGNAL_POLARITY_LOW;
  hsram2.Init.WaitSignalActive = FMC_WAIT_TIMING_BEFORE_WS;
  hsram2.Init.WriteOperation = FMC_WRITE_OPERATION_DISABLE;
  hsram2.Init.WaitSignal = FMC_WAIT_SIGNAL_DISABLE;
  hsram2.Init.ExtendedMode = FMC_EXTENDED_MODE_DISABLE;
  hsram2.Init.AsynchronousWait = FMC_ASYNCHRONOUS_WAIT_DISABLE;
  hsram2.Init.WriteBurst = FMC_WRITE_BURST_DISABLE;
  hsram2.Init.ContinuousClock = FMC_CONTINUOUS_CLOCK_SYNC_ONLY;
  hsram2.Init.PageSize = FMC_PAGE_SIZE_NONE;
  /* Timing */
  Timing.AddressSetupTime = 15;
  Timing.AddressHoldTime = 15;
  Timing.DataSetupTime = 255;
  Timing.BusTurnAroundDuration = 15;
  Timing.CLKDivision = 16;
  Timing.DataLatency = 17;
  Timing.AccessMode = FMC_ACCESS_MODE_A;
  /* ExtTiming */

  if (HAL_SRAM_Init(&hsram2, &Timing, NULL) != HAL_OK)
  {
    Error_Handler( );
  }

}

static void MX_GPIO_Init(void)
{
  GPIO_InitTypeDef GPIO_InitStruct = {0};

  /* GPIO Ports Clock Enable */
  __HAL_RCC_GPIOE_CLK_ENABLE();
  __HAL_RCC_GPIOC_CLK_ENABLE();
  __HAL_RCC_GPIOF_CLK_ENABLE();
  __HAL_RCC_GPIOH_CLK_ENABLE();
  __HAL_RCC_GPIOA_CLK_ENABLE();
  __HAL_RCC_GPIOB_CLK_ENABLE();
  __HAL_RCC_GPIOG_CLK_ENABLE();
  __HAL_RCC_GPIOD_CLK_ENABLE();
  HAL_PWREx_EnableVddIO2();

  /*Configure GPIO pin Output Level */
  HAL_GPIO_WritePin(LED1_GPIO_Port, LED1_Pin, GPIO_PIN_RESET);

  /*Configure GPIO pin Output Level */
  HAL_GPIO_WritePin(NFC_NSS_GPIO_Port, NFC_NSS_Pin, GPIO_PIN_RESET);

  /*Configure GPIO pin Output Level */
  HAL_GPIO_WritePin(USBOTG_PPWR_GPIO_Port, USBOTG_PPWR_Pin, GPIO_PIN_RESET);

  /*Configure GPIO pin : VLCD_Pin */
  GPIO_InitStruct.Pin = VLCD_Pin;
  GPIO_InitStruct.Mode = GPIO_MODE_AF_PP;
  GPIO_InitStruct.Pull = GPIO_NOPULL;
  GPIO_InitStruct.Speed = GPIO_SPEED_FREQ_LOW;
  GPIO_InitStruct.Alternate = GPIO_AF11_LCD;
  HAL_GPIO_Init(VLCD_GPIO_Port, &GPIO_InitStruct);

  /*Configure GPIO pin : LED1_Pin */
  GPIO_InitStruct.Pin = LED1_Pin;
  GPIO_InitStruct.Mode = GPIO_MODE_OUTPUT_PP;
  GPIO_InitStruct.Pull = GPIO_NOPULL;
  GPIO_InitStruct.Speed = GPIO_SPEED_FREQ_LOW;
  HAL_GPIO_Init(LED1_GPIO_Port, &GPIO_InitStruct);

  /*Configure GPIO pin : NFC_NSS_Pin */
  GPIO_InitStruct.Pin = NFC_NSS_Pin;
  GPIO_InitStruct.Mode = GPIO_MODE_OUTPUT_PP;
  GPIO_InitStruct.Pull = GPIO_NOPULL;
  GPIO_InitStruct.Speed = GPIO_SPEED_FREQ_LOW;
  HAL_GPIO_Init(NFC_NSS_GPIO_Port, &GPIO_InitStruct);

  /*Configure GPIO pin : USBOTG_OVRCR_Pin */
  GPIO_InitStruct.Pin = USBOTG_OVRCR_Pin;
  GPIO_InitStruct.Mode = GPIO_MODE_IT_RISING;
  GPIO_InitStruct.Pull = GPIO_NOPULL;
  HAL_GPIO_Init(USBOTG_OVRCR_GPIO_Port, &GPIO_InitStruct);

  /*Configure GPIO pins : CODEC_INT_Pin IOExpander_INT_Pin */
  GPIO_InitStruct.Pin = CODEC_INT_Pin|IOExpander_INT_Pin;
  GPIO_InitStruct.Mode = GPIO_MODE_EVT_RISING;
  GPIO_InitStruct.Pull = GPIO_NOPULL;
  HAL_GPIO_Init(GPIOG, &GPIO_InitStruct);

  /*Configure GPIO pin : USBOTG_PPWR_Pin */
  GPIO_InitStruct.Pin = USBOTG_PPWR_Pin;
  GPIO_InitStruct.Mode = GPIO_MODE_OUTPUT_PP;
  GPIO_InitStruct.Pull = GPIO_NOPULL;
  GPIO_InitStruct.Speed = GPIO_SPEED_FREQ_LOW;
  HAL_GPIO_Init(USBOTG_PPWR_GPIO_Port, &GPIO_InitStruct);

  /*Configure GPIO pin : PT100_DATIN_Pin */
  GPIO_InitStruct.Pin = PT100_DATIN_Pin;
  GPIO_InitStruct.Mode = GPIO_MODE_IT_RISING;
  GPIO_InitStruct.Pull = GPIO_NOPULL;
  HAL_GPIO_Init(PT100_DATIN_GPIO_Port, &GPIO_InitStruct);

  /*Configure GPIO pin : uSD_DETECT_Pin */
  GPIO_InitStruct.Pin = uSD_DETECT_Pin;
  GPIO_InitStruct.Mode = GPIO_MODE_INPUT;
  GPIO_InitStruct.Pull = GPIO_NOPULL;
  HAL_GPIO_Init(uSD_DETECT_GPIO_Port, &GPIO_InitStruct);

}

void StartBlink01(void *argument)
{
  /* USER CODE BEGIN 5 */
  /* Infinite loop */
  for(;;)
  {
	  HAL_GPIO_TogglePin(GPIOB, GPIO_PIN_2);
	  osDelay(500);
  }
  osThreadTerminate(NULL);
  /* USER CODE END 5 */
}

void StartBlink02(void *argument)
{
  /* USER CODE BEGIN StartBlink02 */
  /* Infinite loop */
  for(;;)
  {
	  HAL_GPIO_TogglePin(GPIOB, GPIO_PIN_2);
	  osDelay(600);
  }
  osThreadTerminate(NULL);
  /* USER CODE END StartBlink02 */
}

void HAL_TIM_PeriodElapsedCallback(TIM_HandleTypeDef *htim)
{
  if (htim->Instance == TIM7) {
    HAL_IncTick();
  }
}

void Error_Handler(void)
{
  __disable_irq();
  while (1)
  {
  }
}
